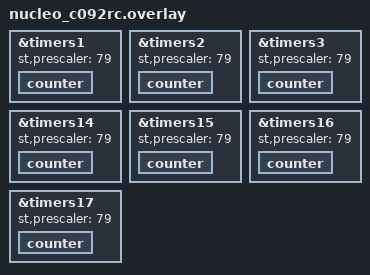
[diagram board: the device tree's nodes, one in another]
/*
 * Copyright (c) 2025 STMicroelectronics
 *
 * SPDX-License-Identifier: Apache-2.0
 */

&timers1 {
	st,prescaler = <79>;
	status = "okay";

	counter {
		status = "okay";
	};
};

&timers2 {
	st,prescaler = <79>;
	status = "okay";

	counter {
		status = "okay";
	};
};

&timers3 {
	st,prescaler = <79>;
	status = "okay";

	counter {
		status = "okay";
	};
};

&timers14 {
	st,prescaler = <79>;
	status = "okay";

	counter {
		status = "okay";
	};
};

&timers15 {
	st,prescaler = <79>;
	status = "okay";

	counter {
		status = "okay";
	};
};

&timers16 {
	st,prescaler = <79>;
	status = "okay";

	counter {
		status = "okay";
	};
};

&timers17 {
	st,prescaler = <79>;
	status = "okay";

	counter {
		status = "okay";
	};
};
